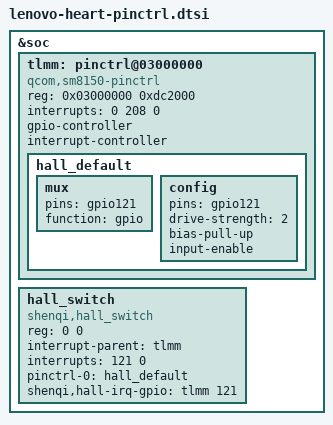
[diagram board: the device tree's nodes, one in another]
/* Copyright (c) 2017-2018, The Linux Foundation. All rights reserved.
 *
 * This program is free software; you can redistribute it and/or modify
 * it under the terms of the GNU General Public License version 2 and
 * only version 2 as published by the Free Software Foundation.
 *
 * This program is distributed in the hope that it will be useful,
 * but WITHOUT ANY WARRANTY; without even the implied warranty of
 * MERCHANTABILITY or FITNESS FOR A PARTICULAR PURPOSE.  See the
 * GNU General Public License for more details.
 */

&soc {
    tlmm: pinctrl@03000000 {
        compatible = "qcom,sm8150-pinctrl";
        reg = <0x03000000 0xdc2000>;
        interrupts = <0 208 0>;
        gpio-controller;
        #gpio-cells = <2>;
        interrupt-controller;
        #interrupt-cells = <2>;

        hall_default: hall_default {
            mux {
                pins = "gpio121";
                function = "gpio";
            };

            config {
                pins = "gpio121";
                drive-strength = <2>;   /* 2 mA */
                bias-pull-up;
                input-enable;
            };
        };
	};

    hall_switch {
        reg = <0 0>;
        compatible = "shenqi,hall_switch";
        interrupt-parent = <&tlmm>;
        interrupts = <121 0>;
        pinctrl-names = "hall_default";
        pinctrl-0 = <&hall_default>;
        shenqi,hall-irq-gpio = <&tlmm 121 0x0>;
//        ssc_vdd-supply = <&pm8994_l19>;
    };
};
